AUTOSAR XML (schema 4-0-3)
package /ComponentTypes
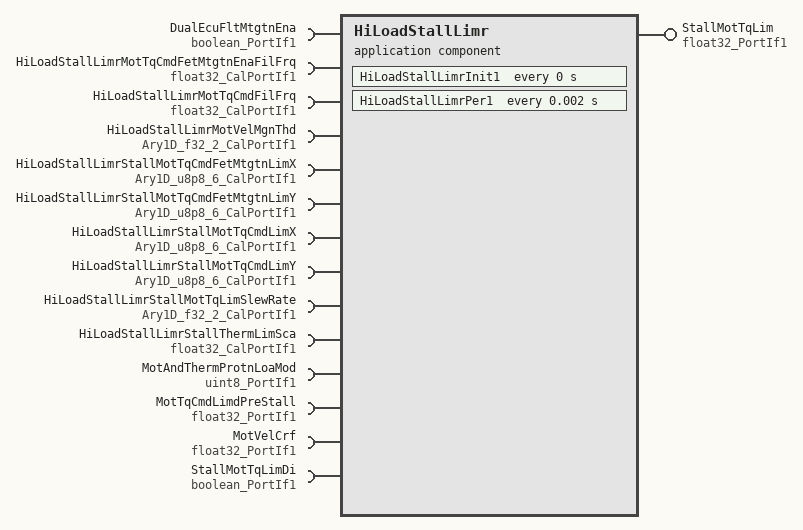
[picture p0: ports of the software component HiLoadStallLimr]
  application sw component type HiLoadStallLimr
    provide port StallMotTqLim: nonqueued-sender-com-spec{data-element=Val, init-value=8.8}, provided-interface=float32_PortIf1
    14 x require port:
      DualEcuFltMtgtnEna: nonqueued-receiver-com-spec{data-element=Logl, filter=data-filter-type=ALWAYS, init-value=0}, required-interface=boolean_PortIf1
      HiLoadStallLimrMotTqCmdFetMtgtnEnaFilFrq: parameter-require-com-spec{init-value=2, parameter=Val}, required-interface=float32_CalPortIf1
      HiLoadStallLimrMotTqCmdFilFrq: parameter-require-com-spec{init-value=2, parameter=Val}, required-interface=float32_CalPortIf1
      HiLoadStallLimrMotVelMgnThd: parameter-require-com-spec{init-value=[1.375, 1.375], parameter=Ary1D}, required-interface=Ary1D_f32_2_CalPortIf1
      HiLoadStallLimrStallMotTqCmdFetMtgtnLimX: parameter-require-com-spec{init-value=[0, 563, 640, 717, 768, 768], parameter=Ary1D}, required-interface=Ary1D_u8p8_6_CalPortIf1
      HiLoadStallLimrStallMotTqCmdFetMtgtnLimY: parameter-require-com-spec{init-value=[768, 768, 512, 256, 0, 0], parameter=Ary1D}, required-interface=Ary1D_u8p8_6_CalPortIf1
      HiLoadStallLimrStallMotTqCmdLimX: parameter-require-com-spec{init-value=[0, 563, 640, 717, 768, 768], parameter=Ary1D}, required-interface=Ary1D_u8p8_6_CalPortIf1
      HiLoadStallLimrStallMotTqCmdLimY: parameter-require-com-spec{init-value=[768, 768, 512, 256, 0, 0], parameter=Ary1D}, required-interface=Ary1D_u8p8_6_CalPortIf1
      HiLoadStallLimrStallMotTqLimSlewRate: parameter-require-com-spec{init-value=[0.101563, 0.101563], parameter=Ary1D}, required-interface=Ary1D_f32_2_CalPortIf1
      HiLoadStallLimrStallThermLimSca: parameter-require-com-spec{init-value=0.5, parameter=Val}, required-interface=float32_CalPortIf1
      MotAndThermProtnLoaMod: nonqueued-receiver-com-spec{data-element=Val, filter=data-filter-type=ALWAYS, init-value=0}, required-interface=uint8_PortIf1
      MotTqCmdLimdPreStall: nonqueued-receiver-com-spec{data-element=Val, filter=data-filter-type=ALWAYS, init-value=0}, required-interface=float32_PortIf1
      MotVelCrf: nonqueued-receiver-com-spec{data-element=Val, filter=data-filter-type=ALWAYS, init-value=0}, required-interface=float32_PortIf1
      StallMotTqLimDi: nonqueued-receiver-com-spec{data-element=Logl, filter=data-filter-type=ALWAYS, init-value=0}, required-interface=boolean_PortIf1
    behavior HiLoadStallLimr_InternalBehavior
      ar-typed-per-instance-memorys:
        8 x data, all with sw-calibration-access=READ-ONLY:
          dHiLoadStallLimrStallMotTqCmd: type=float32
          dHiLoadStallLimrStallMotTqCmdFild: type=float32
          dHiLoadStallLimrStallMotTqLim: type=float32
          FetLoaMtgtnCalIdx: type=uint8
          StallMotTqCmdFetMtgtnFil: type=FilLpRec1
          StallMotTqCmdFil: type=FilLpRec1
          StallMotTqLimFetMtgtnPrev: type=float32
          StallMotTqLimPrev: type=float32
      timing event HiLoadStallLimr_InitEvent: start-on-event=HiLoadStallLimrInit1, period=0
      timing event TMT_HiLoadStallLimrPer1: start-on-event=HiLoadStallLimrPer1, period=0.002
      runnable HiLoadStallLimrInit1
        data-receive-point-by-arguments:
          access REC_MotAndThermProtnLoaMod_Val: accessed-variable=MotAndThermProtnLoaMod.Val
      runnable HiLoadStallLimrPer1
        data-receive-point-by-arguments:
          5 x access:
            REC_DualEcuFltMtgtnEna_Logl: accessed-variable=DualEcuFltMtgtnEna.Logl
            REC_MotAndThermProtnLoaMod_Val: accessed-variable=MotAndThermProtnLoaMod.Val
            REC_MotTqCmdLimdPreStall_Val: accessed-variable=MotTqCmdLimdPreStall.Val
            REC_MotVelCrf_Val: accessed-variable=MotVelCrf.Val
            REC_StallMotTqLimDi_Logl: accessed-variable=StallMotTqLimDi.Logl
        data-send-points:
          access SEND_StallMotTqLim_Val: accessed-variable=StallMotTqLim.Val
  swc implementation HiLoadStallLimr_Implementation: behavior=HiLoadStallLimr_InternalBehavior
    code-descriptors:
      code Default: artifact-descriptors=autosar-engineering-object={short-label=Default, category=SWSRC}
